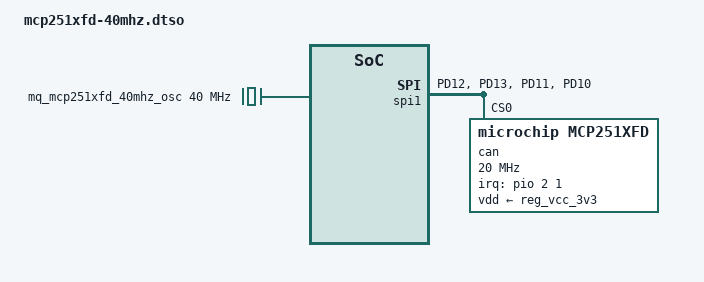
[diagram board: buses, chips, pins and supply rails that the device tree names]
// SPDX-License-Identifier: (GPL-2.0+ OR MIT)
// Mangue OS header overlay mcp251xfd-40mhz — GENERATED by tools/gen_overlays.py,
// edit overlays/header_table.py instead.
//
// pin port  role
//  19 PD12  mosi
//  21 PD13  miso
//  23 PD11  clk
//  24 PD10  cs0
//  22 PC1   int
// device: network interface canN (ip link set canN up type can bitrate ...)

/dts-v1/;
/plugin/;

#include <dt-bindings/gpio/gpio.h>
#include <dt-bindings/interrupt-controller/irq.h>
#include <dt-bindings/input/linux-event-codes.h>

&{/} {
	mq_mcp251xfd_40mhz_osc: mcp251xfd-40mhz-osc {
		compatible = "fixed-clock";
		#clock-cells = <0>;
		clock-frequency = <40000000>;
	};
};

&pio {
	mq_mcp251xfd_40mhz_pins: mcp251xfd-40mhz-pins {
		pins = "PD12", "PD13", "PD11", "PD10";
		function = "spi1";
	};
};

&spi1 {
	pinctrl-names = "default";
	pinctrl-0 = <&mq_mcp251xfd_40mhz_pins>;
	#address-cells = <1>;
	#size-cells = <0>;
	status = "okay";

	can@0 {
		compatible = "microchip,mcp251xfd";
		reg = <0>;
		clocks = <&mq_mcp251xfd_40mhz_osc>;
		interrupts-extended = <&pio 2 1 IRQ_TYPE_LEVEL_LOW>;
		spi-max-frequency = <20000000>;
		vdd-supply = <&reg_vcc_3v3>;
	};
};
